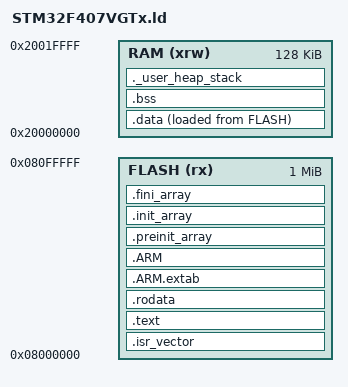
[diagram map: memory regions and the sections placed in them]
/* STM32F407VG: 1 MB flash, 128 KB SRAM (+64 KB CCM, unused) */

ENTRY(Reset_Handler)

MEMORY
{
    FLASH (rx)  : ORIGIN = 0x08000000, LENGTH = 1024K
    RAM   (xrw) : ORIGIN = 0x20000000, LENGTH = 128K
}

_estack = ORIGIN(RAM) + LENGTH(RAM);

/* Main stack: used by main() before the scheduler starts, then by interrupts. */
_Min_Stack_Size = 0x800;

SECTIONS
{
    .isr_vector :
    {
        . = ALIGN(4);
        KEEP(*(.isr_vector))
        . = ALIGN(4);
    } >FLASH

    .text :
    {
        . = ALIGN(4);
        *(.text*)
        *(.glue_7) *(.glue_7t)
        *(.eh_frame)
        KEEP(*(.init))
        KEEP(*(.fini))
        . = ALIGN(4);
    } >FLASH

    .rodata :
    {
        . = ALIGN(4);
        *(.rodata*)
        . = ALIGN(4);
    } >FLASH

    .ARM.extab : { *(.ARM.extab* .gnu.linkonce.armextab.*) } >FLASH
    .ARM :
    {
        __exidx_start = .;
        *(.ARM.exidx*)
        __exidx_end = .;
    } >FLASH

    .preinit_array :
    {
        PROVIDE_HIDDEN(__preinit_array_start = .);
        KEEP(*(.preinit_array*))
        PROVIDE_HIDDEN(__preinit_array_end = .);
    } >FLASH
    .init_array :
    {
        PROVIDE_HIDDEN(__init_array_start = .);
        KEEP(*(SORT(.init_array.*)))
        KEEP(*(.init_array*))
        PROVIDE_HIDDEN(__init_array_end = .);
    } >FLASH
    .fini_array :
    {
        PROVIDE_HIDDEN(__fini_array_start = .);
        KEEP(*(SORT(.fini_array.*)))
        KEEP(*(.fini_array*))
        PROVIDE_HIDDEN(__fini_array_end = .);
    } >FLASH

    _sidata = LOADADDR(.data);
    .data :
    {
        . = ALIGN(4);
        _sdata = .;
        *(.data*)
        . = ALIGN(4);
        _edata = .;
    } >RAM AT> FLASH

    .bss (NOLOAD) :
    {
        . = ALIGN(4);
        _sbss = .;
        __bss_start__ = _sbss;
        *(.bss*)
        *(COMMON)
        . = ALIGN(4);
        _ebss = .;
        __bss_end__ = _ebss;
    } >RAM

    /* newlib's malloc grows up from `end` (see _sbrk); this just checks the stack still fits. */
    ._user_heap_stack (NOLOAD) :
    {
        . = ALIGN(8);
        PROVIDE(end = .);
        . = . + _Min_Stack_Size;
        . = ALIGN(8);
    } >RAM

    .ARM.attributes 0 : { *(.ARM.attributes) }
}
